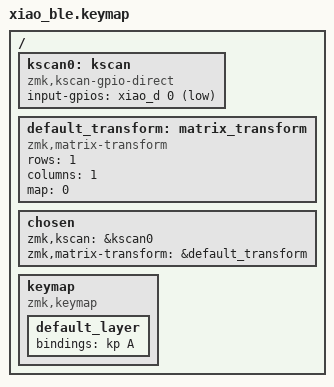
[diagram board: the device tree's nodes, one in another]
#include <behaviors.dtsi>
#include <dt-bindings/zmk/keys.h>

/ {
    kscan0: kscan {
        compatible = "zmk,kscan-gpio-direct";

        input-gpios =
            <&xiao_d 0 (GPIO_ACTIVE_LOW | GPIO_PULL_UP)>;
    };

    default_transform: matrix_transform {
        compatible = "zmk,matrix-transform";

        rows = <1>;
        columns = <1>;

        map = <
            0
        >;
    };

    chosen {
        zmk,kscan = &kscan0;
        zmk,matrix-transform = &default_transform;
    };

    keymap {
        compatible = "zmk,keymap";

        default_layer {
            bindings = <
                &kp A
            >;
        };
    };
};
